# ATSAML10E16A register map
Vendor: Microchip Technology; Series: SAML10; File version: 0
CPU: CM23 r0p0, selectable endian, MPU, no FPU, 2 interrupt priority bits
Registers are 32-bit, read-write, reset 0x0 unless marked. A register's access mark holds for its fields unless they carry their own. Offsets are from the block's base; [hi:lo] are bit positions; {n}, {i} and the like mark numbered series; 'fields as' and 'values as' point back to an identical list.

## AC — Analog Comparators
Base 0x40003400; register names take the prefix AC_
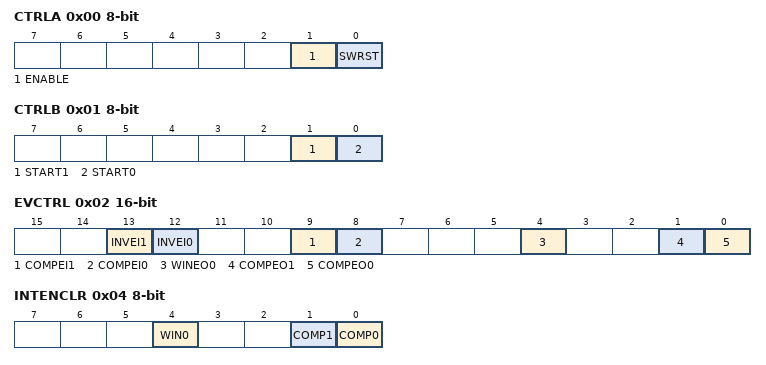
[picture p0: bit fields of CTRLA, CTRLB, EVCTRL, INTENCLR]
0x00 CTRLA 8-bit — Control A
  [1] ENABLE
  [0] SWRST — Software Reset
0x01 CTRLB 8-bit wo — Control B
  [1] START1 — Comparator 1 Start Comparison
  [0] START0 — Comparator 0 Start Comparison
0x02 EVCTRL 16-bit — Event Control
  [13] INVEI1 — Comparator 1 Input Event Invert Enable
  [12] INVEI0 — Comparator 0 Input Event Invert Enable
  [9] COMPEI1 — Comparator 1 Event Input Enable
  [8] COMPEI0 — Comparator 0 Event Input Enable
  [4] WINEO0 — Window 0 Event Output Enable
  [1] COMPEO1 — Comparator 1 Event Output Enable
  [0] COMPEO0 — Comparator 0 Event Output Enable
0x04 INTENCLR 8-bit — Interrupt Enable Clear
  [4] WIN0 — Window 0 Interrupt Enable
  [1] COMP1 — Comparator 1 Interrupt Enable
  [0] COMP0 — Comparator 0 Interrupt Enable
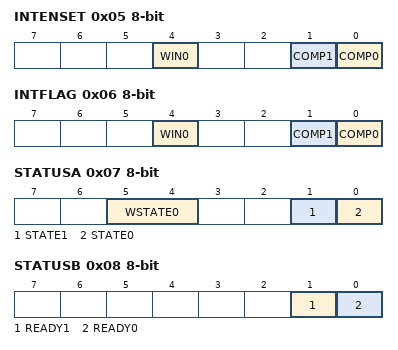
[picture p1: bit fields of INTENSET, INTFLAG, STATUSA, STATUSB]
0x05 INTENSET 8-bit — Interrupt Enable Set
  fields as INTENCLR
0x06 INTFLAG 8-bit — Interrupt Flag Status and Clear
  [4] WIN0 — Window 0
  [1] COMP1 — Comparator 1
  [0] COMP0 — Comparator 0
0x07 STATUSA 8-bit ro
  [5:4] WSTATE0 — Window 0 Current State
    0=ABOVE (Signal is above window); 1=INSIDE (Signal is inside window); 2=BELOW (Signal is below window)
  [1] STATE1 — Comparator 1 Current State
  [0] STATE0 — Comparator 0 Current State
0x08 STATUSB 8-bit ro
  [1] READY1 — Comparator 1 Ready
  [0] READY0 — Comparator 0 Ready
0x09 DBGCTRL 8-bit — Debug Control
  [0] DBGRUN — Debug Run
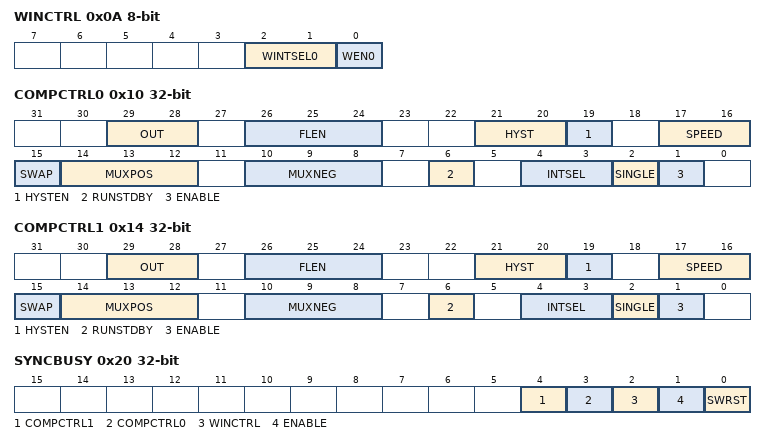
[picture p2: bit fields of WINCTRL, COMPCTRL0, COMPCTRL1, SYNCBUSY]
0x0A WINCTRL 8-bit — Window Control
  [2:1] WINTSEL0 — Window 0 Interrupt Selection
    0=ABOVE (Interrupt on signal above window); 1=INSIDE (Interrupt on signal inside window); 2=BELOW (Interrupt on signal below window); 3=OUTSIDE (Interrupt on signal outside window)
  [0] WEN0 — Window 0 Mode Enable
{0xC+i} SCALER[{i}] (i=0..1) 8-bit — Scaler n
  [5:0] VALUE — Scaler Value
0x10 COMPCTRL0 — Comparator Control 0
  [29:28] OUT — Output
    0=OFF (The output of COMPn is not routed to the COMPn I/O port); 1=ASYNC (The asynchronous output of COMPn is routed to the COMPn I/O port); 2=SYNC (The synchronous output (including filtering) of COMPn is routed to the COMPn I/O port)
  [26:24] FLEN — Filter Length
    0=OFF (No filtering); 1=MAJ3 (3-bit majority function (2 of 3)); 2=MAJ5 (5-bit majority function (3 of 5))
  [21:20] HYST — Hysteresis Level
    0=50mV; 1=70mV; 2=90mV; 3=110mV
  [19] HYSTEN — Hysteresis Enable
  [17:16] SPEED — Speed Selection
    0=LOW (Low speed); 1=MEDLOW (Medium low speed); 2=MEDHIGH (Medium high speed); 3=HIGH (High speed)
  [15] SWAP — Swap Inputs and Invert
  [14:12] MUXPOS — Positive Input Mux Selection
    {v}=PIN{v} (I/O pin {v}) (v=0..3); 4=VSCALE (VDD Scaler)
  [10:8] MUXNEG — Negative Input Mux Selection
    {v}=PIN{v} (I/O pin {v}) (v=0..3); 4=GND (Ground); 5=VSCALE (VDD scaler); 6=BANDGAP (Internal bandgap voltage); 7=DAC (DAC output (on AC0))
  [6] RUNSTDBY — Run in Standby
  [4:3] INTSEL — Interrupt Selection
    0=TOGGLE (Interrupt on comparator output toggle); 1=RISING (Interrupt on comparator output rising); 2=FALLING (Interrupt on comparator output falling); 3=EOC (Interrupt on end of comparison (single-shot mode only))
  [2] SINGLE — Single-Shot Mode
  [1] ENABLE
0x14 COMPCTRL1 — Comparator Control 1
  [29:28] OUT — Output
    values as COMPCTRL0.OUT
  [26:24] FLEN — Filter Length
    values as COMPCTRL0.FLEN
  [21:20] HYST — Hysteresis Level
    0=50mV; 1=70mV; 2=90mV; 3=110mV
  [19] HYSTEN — Hysteresis Enable
  [17:16] SPEED — Speed Selection
    values as COMPCTRL0.SPEED
  [15] SWAP — Swap Inputs and Invert
  [14:12] MUXPOS — Positive Input Mux Selection
    {v}=PIN{v} (I/O pin {v}) (v=0..3); 4=VSCALE (VDD Scaler)
  [10:8] MUXNEG — Negative Input Mux Selection
    {v}=PIN{v} (I/O pin {v}) (v=0..3); 4=GND (Ground); 5=VSCALE (VDD scaler); 6=BANDGAP (Internal bandgap voltage); 7=OPAMP (OPAMP output (on AC1))
  [6] RUNSTDBY — Run in Standby
  [4:3] INTSEL — Interrupt Selection
    values as COMPCTRL0.INTSEL
  [2] SINGLE — Single-Shot Mode
  [1] ENABLE
0x20 SYNCBUSY ro — Synchronization Busy
  [4] COMPCTRL1 — COMPCTRL 1 Synchronization Busy
  [3] COMPCTRL0 — COMPCTRL 0 Synchronization Busy
  [2] WINCTRL — WINCTRL Synchronization Busy
  [1] ENABLE — Enable Synchronization Busy
  [0] SWRST — Software Reset Synchronization Busy
